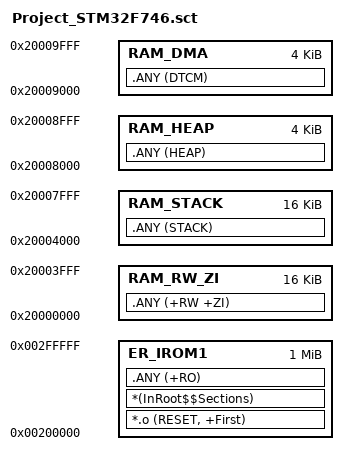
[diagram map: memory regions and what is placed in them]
LR_IROM1   0x00200000  0x00100000     ; load region size_region
;LR_IROM1    0x08000000  0x00100000
{ 
  ER_IROM1  0x00200000  0x00100000   ; load address = execution address
  ;ER_IROM1  0x08000000   0x00100000   ; load address = execution address
  {
   *.o (RESET, +First)
   *(InRoot$$Sections)
   .ANY (+RO)
  }
  
  RAM_RW_ZI  0x20000000  0x4000  
  {
    .ANY (+RW +ZI)                
  }
    
  RAM_STACK  0x20004000  0x4000  
  { 
    .ANY (STACK)                   
  }                                
  
  RAM_HEAP   0x20008000  0x1000  
  {
    .ANY (HEAP)                   
  }                               
  RAM_DMA   0x20009000   0x1000  
  {
    .ANY (DTCM)                   
  }                               
}                                 
                                  

